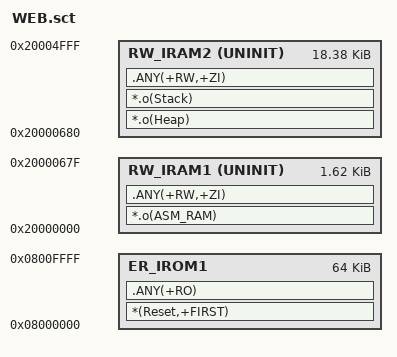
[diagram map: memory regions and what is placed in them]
LR1 0x08000000 0x10000
{
    ER_IROM1 0x08000000 0x10000
    {
        *(Reset,+FIRST)
        .ANY(+RO)
    }


    RW_IRAM1 0x20000000 UNINIT 0x680                    ; RW data
    {
        *.o(ASM_RAM)
        .ANY(+RW,+ZI)
    }

    RW_IRAM2 0x20000680 UNINIT 0x00005000-0x680       ; RW data
    {
        *.o(Heap)
        *.o(Stack)
        .ANY(+RW,+ZI)
    }


}
